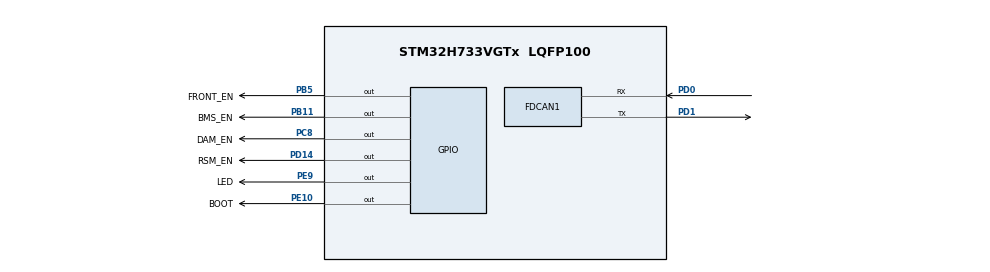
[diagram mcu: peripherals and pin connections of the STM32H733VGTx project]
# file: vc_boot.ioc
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CORTEX_M7.default_mode_Activation=1
FDCAN1.AutoRetransmission=ENABLE
FDCAN1.CalculateBaudRateNominal=1000000
FDCAN1.CalculateTimeBitNominal=1000
FDCAN1.CalculateTimeQuantumNominal=62.5
FDCAN1.DataPrescaler=3
FDCAN1.DataSyncJumpWidth=2
FDCAN1.DataTimeSeg1=5
FDCAN1.DataTimeSeg2=2
FDCAN1.ExtFiltersNbr=1
FDCAN1.FrameFormat=FDCAN_FRAME_FD_NO_BRS
FDCAN1.NominalPrescaler=6
FDCAN1.NominalSyncJumpWidth=2
FDCAN1.NominalTimeSeg1=13
FDCAN1.NominalTimeSeg2=2
FDCAN1.RxFifo0ElmtSize=FDCAN_DATA_BYTES_64
FDCAN1.RxFifo0ElmtsNbr=32
FDCAN1.RxFifo1ElmtSize=FDCAN_DATA_BYTES_64
FDCAN1.StdFiltersNbr=1
FDCAN1.TxElmtSize=FDCAN_DATA_BYTES_64
FDCAN1.TxFifoQueueElmtsNbr=32
Mcu.Family=STM32H7
Mcu.Name=STM32H733VGTx
Mcu.Package=LQFP100
NVIC.FDCAN1_IT0_IRQn=true\:5\:0\:true\:false\:true\:true\:true\:true
NVIC.FDCAN1_IT1_IRQn=true\:5\:0\:true\:false\:true\:true\:true\:true
NVIC.PriorityGroup=NVIC_PRIORITYGROUP_4
NVIC.RCC_IRQn=true\:5\:0\:true\:false\:true\:true\:false\:true
NVIC.TIM6_DAC_IRQn=true\:15\:0\:false\:false\:true\:false\:true\:true
NVIC.TimeBase=TIM6_DAC_IRQn
NVIC.TimeBaseIP=TIM6
PA13(JTMS/SWDIO).Mode=Trace_Asynchronous_SW
PA13(JTMS/SWDIO).Signal=DEBUG_JTMS-SWDIO
PA14(JTCK/SWCLK).Mode=Trace_Asynchronous_SW
PA14(JTCK/SWCLK).Signal=DEBUG_JTCK-SWCLK
PB11.GPIO_Label=BMS_EN
PB11.PinState=GPIO_PIN_SET
PB11.Signal=GPIO_Output
PB3(JTDO/TRACESWO).Mode=Trace_Asynchronous_SW
PB3(JTDO/TRACESWO).Signal=DEBUG_JTDO-SWO
PB5.GPIO_Label=FRONT_EN
PB5.PinState=GPIO_PIN_SET
PB5.Signal=GPIO_Output
PC8.GPIO_Label=DAM_EN
PC8.PinState=GPIO_PIN_SET
PC8.Signal=GPIO_Output
PD0.Mode=FDCAN_Activate
PD0.Signal=FDCAN1_RX
PD1.Mode=FDCAN_Activate
PD1.Signal=FDCAN1_TX
PD14.GPIO_Label=RSM_EN
PD14.PinState=GPIO_PIN_SET
PD14.Signal=GPIO_Output
PE10.GPIO_Label=BOOT
PE10.PinState=GPIO_PIN_SET
PE10.Signal=GPIO_Output
PE9.GPIO_Label=LED
PE9.Signal=GPIO_Output
PH0-OSC_IN.Mode=HSE-External-Oscillator
PH0-OSC_IN.Signal=RCC_OSC_IN
PH1-OSC_OUT.Mode=HSE-External-Oscillator
PH1-OSC_OUT.Signal=RCC_OSC_OUT
ProjectManager.HeapSize=0x0
ProjectManager.StackSize=0x400
ProjectManager.TargetToolchain=EWARM V8.50
RCC.ADCFreq_Value=96000000
RCC.APB1Freq_Value=125000000
RCC.APB2Freq_Value=125000000
RCC.APB3Freq_Value=125000000
RCC.APB4Freq_Value=125000000
RCC.CortexFreq_Value=250000000
RCC.D1PPRE=RCC_APB3_DIV2
RCC.D2PPRE1=RCC_APB1_DIV2
RCC.D2PPRE2=RCC_APB2_DIV2
RCC.D3PPRE=RCC_APB4_DIV2
RCC.DIVM1=1
RCC.DIVM2=1
RCC.DIVM3=1
RCC.DIVN1=31
RCC.DIVN2=24
RCC.DIVN3=24
RCC.DIVP1=1
RCC.DIVQ1=1
RCC.FDCANCLockSelection=RCC_FDCANCLKSOURCE_PLL2
RCC.HCLKFreq_Value=250000000
RCC.HSE_VALUE=8000000
RCC.PLL2FRACN=0
RCC.PLL3FRACN=0
RCC.PLLFRACN=2048
RCC.PLLSourceVirtual=RCC_PLLSOURCE_HSE
RCC.SYSCLKFreq_VALUE=250000000
RCC.SYSCLKSource=RCC_SYSCLKSOURCE_PLLCLK
RCC.USBFreq_Value=250000000
VP_MEMORYMAP_VS_MEMORYMAP.Mode=CurAppReg
VP_SYS_VS_tim6.Mode=TIM6
board=custom

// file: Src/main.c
/* USER CODE BEGIN Header */
/**
 ******************************************************************************
 * @file           : main.c
 * @brief          : Main program body
 ******************************************************************************
 * @attention
 *
 * Copyright (c) 2026 STMicroelectronics.
 * All rights reserved.
 *
 * This software is licensed under terms that can be found in the LICENSE file
 * in the root directory of this software component.
 * If no LICENSE file comes with this software, it is provided AS-IS.
 *
 ******************************************************************************
 */
/* USER CODE END Header */
#include "main.h"

/* USER CODE BEGIN Includes */
#include "bootloader_vc.h"
/* USER CODE END Includes */

FDCAN_HandleTypeDef hfdcan1;

void        SystemClock_Config(void);
static void MPU_Config(void);
static void MX_GPIO_Init(void);
static void MX_FDCAN1_Init(void);

int main(void)
{
    /* USER CODE BEGIN 1 */
    bootloader_preinit();
    /* USER CODE END 1 */

    /* MPU Configuration--------------------------------------------------------*/
    MPU_Config();

    /* MCU Configuration--------------------------------------------------------*/

    /* Reset of all peripherals, Initializes the Flash interface and the Systick. */
    HAL_Init();

    /* Configure the system clock */
    SystemClock_Config();

    /* Initialize all configured peripherals */
    MX_GPIO_Init();
    MX_FDCAN1_Init();
    /* USER CODE BEGIN 2 */
    bootloader_init();
    /* USER CODE END 2 */

    /* Infinite loop */
    while (1)
    {

    }
}

void SystemClock_Config(void)
{
    RCC_OscInitTypeDef RCC_OscInitStruct = { 0 };
    RCC_ClkInitTypeDef RCC_ClkInitStruct = { 0 };

    /** Supply configuration update enable
     */
    HAL_PWREx_ConfigSupply(PWR_LDO_SUPPLY);

    /** Configure the main internal regulator output voltage
     */
    __HAL_PWR_VOLTAGESCALING_CONFIG(PWR_REGULATOR_VOLTAGE_SCALE0);

    while (!__HAL_PWR_GET_FLAG(PWR_FLAG_VOSRDY))
    {
    }

    /** Initializes the RCC Oscillators according to the specified parameters
     * in the RCC_OscInitTypeDef structure.
     */
    RCC_OscInitStruct.OscillatorType = RCC_OSCILLATORTYPE_HSE;
    RCC_OscInitStruct.HSEState       = RCC_HSE_ON;
    RCC_OscInitStruct.PLL.PLLState   = RCC_PLL_ON;
    RCC_OscInitStruct.PLL.PLLSource  = RCC_PLLSOURCE_HSE;
    RCC_OscInitStruct.PLL.PLLM       = 1;
    RCC_OscInitStruct.PLL.PLLN       = 31;
    RCC_OscInitStruct.PLL.PLLP       = 1;
    RCC_OscInitStruct.PLL.PLLQ       = 1;
    RCC_OscInitStruct.PLL.PLLR       = 2;
    RCC_OscInitStruct.PLL.PLLRGE     = RCC_PLL1VCIRANGE_3;
    RCC_OscInitStruct.PLL.PLLVCOSEL  = RCC_PLL1VCOWIDE;
    RCC_OscInitStruct.PLL.PLLFRACN   = 2048;
    if (HAL_RCC_OscConfig(&RCC_OscInitStruct) != HAL_OK)
    {
        Error_Handler();
    }

    /** Initializes the CPU, AHB and APB buses clocks
     */
    RCC_ClkInitStruct.ClockType = RCC_CLOCKTYPE_HCLK | RCC_CLOCKTYPE_SYSCLK | RCC_CLOCKTYPE_PCLK1 |
                                  RCC_CLOCKTYPE_PCLK2 | RCC_CLOCKTYPE_D3PCLK1 | RCC_CLOCKTYPE_D1PCLK1;
    RCC_ClkInitStruct.SYSCLKSource   = RCC_SYSCLKSOURCE_PLLCLK;
    RCC_ClkInitStruct.SYSCLKDivider  = RCC_SYSCLK_DIV1;
    RCC_ClkInitStruct.AHBCLKDivider  = RCC_HCLK_DIV1;
    RCC_ClkInitStruct.APB3CLKDivider = RCC_APB3_DIV2;
    RCC_ClkInitStruct.APB1CLKDivider = RCC_APB1_DIV2;
    RCC_ClkInitStruct.APB2CLKDivider = RCC_APB2_DIV2;
    RCC_ClkInitStruct.APB4CLKDivider = RCC_APB4_DIV2;

    if (HAL_RCC_ClockConfig(&RCC_ClkInitStruct, FLASH_LATENCY_3) != HAL_OK)
    {
        Error_Handler();
    }
}

static void MX_FDCAN1_Init(void)
{

    hfdcan1.Instance                  = FDCAN1;
    hfdcan1.Init.FrameFormat          = FDCAN_FRAME_FD_BRS;
    hfdcan1.Init.Mode                 = FDCAN_MODE_NORMAL;
    hfdcan1.Init.AutoRetransmission   = ENABLE;
    hfdcan1.Init.TransmitPause        = ENABLE;
    hfdcan1.Init.ProtocolException    = ENABLE;
    hfdcan1.Init.NominalPrescaler     = 1;
    hfdcan1.Init.NominalSyncJumpWidth = 15;
    hfdcan1.Init.NominalTimeSeg1      = 80;
    hfdcan1.Init.NominalTimeSeg2      = 15;
    hfdcan1.Init.DataPrescaler        = 1;
    hfdcan1.Init.DataSyncJumpWidth    = 4;
    hfdcan1.Init.DataTimeSeg1         = 19;
    hfdcan1.Init.DataTimeSeg2         = 4;
    hfdcan1.Init.MessageRAMOffset     = 0;
    hfdcan1.Init.StdFiltersNbr        = 1;
    hfdcan1.Init.ExtFiltersNbr        = 1;
    hfdcan1.Init.RxFifo0ElmtsNbr      = 32;
    hfdcan1.Init.RxFifo0ElmtSize      = FDCAN_DATA_BYTES_64;
    hfdcan1.Init.RxFifo1ElmtsNbr      = 0;
    hfdcan1.Init.RxFifo1ElmtSize      = FDCAN_DATA_BYTES_64;
    hfdcan1.Init.RxBuffersNbr         = 0;
    hfdcan1.Init.RxBufferSize         = FDCAN_DATA_BYTES_8;
    hfdcan1.Init.TxEventsNbr          = 0;
    hfdcan1.Init.TxBuffersNbr         = 0;
    hfdcan1.Init.TxFifoQueueElmtsNbr  = 32;
    hfdcan1.Init.TxFifoQueueMode      = FDCAN_TX_FIFO_OPERATION;
    hfdcan1.Init.TxElmtSize           = FDCAN_DATA_BYTES_64;
    if (HAL_FDCAN_Init(&hfdcan1) != HAL_OK)
    {
        Error_Handler();
    }
    /* USER CODE BEGIN FDCAN1_Init 2 */
    HAL_FDCAN_ConfigTxDelayCompensation(&hfdcan1, 15, 0);
    HAL_FDCAN_EnableTxDelayCompensation(&hfdcan1);
    /* USER CODE END FDCAN1_Init 2 */
}

static void MX_GPIO_Init(void)
{
    GPIO_InitTypeDef GPIO_InitStruct = { 0 };

    /* GPIO Ports Clock Enable */
    __HAL_RCC_GPIOH_CLK_ENABLE();
    __HAL_RCC_GPIOE_CLK_ENABLE();
    __HAL_RCC_GPIOB_CLK_ENABLE();
    __HAL_RCC_GPIOD_CLK_ENABLE();
    __HAL_RCC_GPIOC_CLK_ENABLE();
    __HAL_RCC_GPIOA_CLK_ENABLE();

    /*Configure GPIO pin Output Level */
    HAL_GPIO_WritePin(LED_GPIO_Port, LED_Pin, GPIO_PIN_RESET);

    /*Configure GPIO pin Output Level */
    HAL_GPIO_WritePin(BOOT_GPIO_Port, BOOT_Pin, GPIO_PIN_SET);

    /*Configure GPIO pin Output Level */
    HAL_GPIO_WritePin(GPIOB, BMS_EN_Pin | FRONT_EN_Pin, GPIO_PIN_SET);

    /*Configure GPIO pin Output Level */
    HAL_GPIO_WritePin(RSM_EN_GPIO_Port, RSM_EN_Pin, GPIO_PIN_SET);

    /*Configure GPIO pin Output Level */
    HAL_GPIO_WritePin(DAM_EN_GPIO_Port, DAM_EN_Pin, GPIO_PIN_SET);

    /*Configure GPIO pins : LED_Pin BOOT_Pin */
    GPIO_InitStruct.Pin   = LED_Pin | BOOT_Pin;
    GPIO_InitStruct.Mode  = GPIO_MODE_OUTPUT_PP;
    GPIO_InitStruct.Pull  = GPIO_NOPULL;
    GPIO_InitStruct.Speed = GPIO_SPEED_FREQ_LOW;
    HAL_GPIO_Init(GPIOE, &GPIO_InitStruct);

    /*Configure GPIO pins : BMS_EN_Pin FRONT_EN_Pin */
    GPIO_InitStruct.Pin   = BMS_EN_Pin | FRONT_EN_Pin;
    GPIO_InitStruct.Mode  = GPIO_MODE_OUTPUT_PP;
    GPIO_InitStruct.Pull  = GPIO_NOPULL;
    GPIO_InitStruct.Speed = GPIO_SPEED_FREQ_LOW;
    HAL_GPIO_Init(GPIOB, &GPIO_InitStruct);

    /*Configure GPIO pin : RSM_EN_Pin */
    GPIO_InitStruct.Pin   = RSM_EN_Pin;
    GPIO_InitStruct.Mode  = GPIO_MODE_OUTPUT_PP;
    GPIO_InitStruct.Pull  = GPIO_NOPULL;
    GPIO_InitStruct.Speed = GPIO_SPEED_FREQ_LOW;
    HAL_GPIO_Init(RSM_EN_GPIO_Port, &GPIO_InitStruct);

    /*Configure GPIO pin : DAM_EN_Pin */
    GPIO_InitStruct.Pin   = DAM_EN_Pin;
    GPIO_InitStruct.Mode  = GPIO_MODE_OUTPUT_PP;
    GPIO_InitStruct.Pull  = GPIO_NOPULL;
    GPIO_InitStruct.Speed = GPIO_SPEED_FREQ_LOW;
    HAL_GPIO_Init(DAM_EN_GPIO_Port, &GPIO_InitStruct);

}

/* MPU Configuration */

void MPU_Config(void)
{
    MPU_Region_InitTypeDef MPU_InitStruct = { 0 };

    /* Disables the MPU */
    HAL_MPU_Disable();

    /** Initializes and configures the Region and the memory to be protected
     */
    MPU_InitStruct.Enable           = MPU_REGION_ENABLE;
    MPU_InitStruct.Number           = MPU_REGION_NUMBER0;
    MPU_InitStruct.BaseAddress      = 0x0;
    MPU_InitStruct.Size             = MPU_REGION_SIZE_4GB;
    MPU_InitStruct.SubRegionDisable = 0x87;
    MPU_InitStruct.TypeExtField     = MPU_TEX_LEVEL0;
    MPU_InitStruct.AccessPermission = MPU_REGION_NO_ACCESS;
    MPU_InitStruct.DisableExec      = MPU_INSTRUCTION_ACCESS_DISABLE;
    MPU_InitStruct.IsShareable      = MPU_ACCESS_SHAREABLE;
    MPU_InitStruct.IsCacheable      = MPU_ACCESS_NOT_CACHEABLE;
    MPU_InitStruct.IsBufferable     = MPU_ACCESS_NOT_BUFFERABLE;

    HAL_MPU_ConfigRegion(&MPU_InitStruct);
    /* Enables the MPU */
    HAL_MPU_Enable(MPU_PRIVILEGED_DEFAULT);
}

void HAL_TIM_PeriodElapsedCallback(TIM_HandleTypeDef *htim)
{
    if (htim->Instance == TIM6)
    {
        HAL_IncTick();
    }
}

void Error_Handler(void)
{
    __disable_irq();
    while (1)
    {
    }
}
